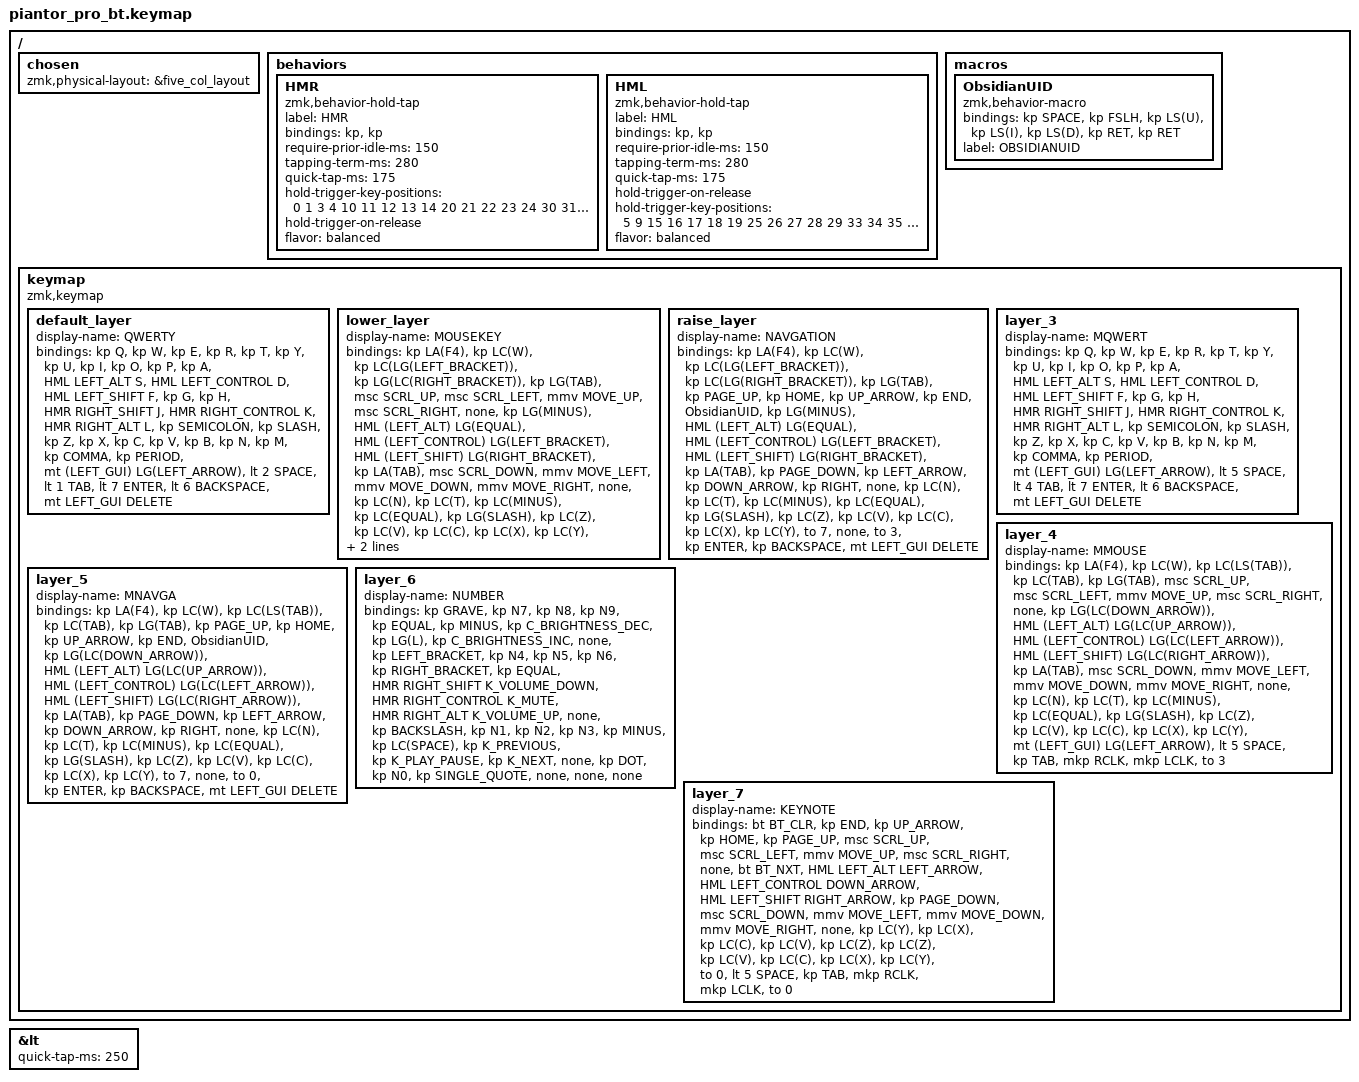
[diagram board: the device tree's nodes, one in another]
/*
 * Copyright (c) 2020 The ZMK Contributors
 *
 * SPDX-License-Identifier: MIT
 */

#include <behaviors.dtsi>
#include <dt-bindings/zmk/bt.h>
#include <dt-bindings/zmk/keys.h>
#include <dt-bindings/zmk/pointing.h>

&lt { quick-tap-ms = <250>; };

/ {
    chosen { zmk,physical-layout = &five_col_layout; };
};

/ {
    behaviors {
        HMR: HMR {
            compatible = "zmk,behavior-hold-tap";
            label = "HMR";
            bindings = <&kp>, <&kp>;

            #binding-cells = <2>;
            require-prior-idle-ms = <150>;
            tapping-term-ms = <280>;
            quick-tap-ms = <175>;
            hold-trigger-key-positions = <0 1 3 4 10 11 12 13 14 20 21 22 23 24 30 31 32 2>;
            hold-trigger-on-release;
            flavor = "balanced";
        };

        HML: HML {
            compatible = "zmk,behavior-hold-tap";
            label = "HML";
            bindings = <&kp>, <&kp>;

            #binding-cells = <2>;
            require-prior-idle-ms = <150>;
            tapping-term-ms = <280>;
            quick-tap-ms = <175>;
            hold-trigger-on-release;
            hold-trigger-key-positions = <5 9 15 16 17 18 19 25 26 27 28 29 33 34 35 6 7 8>;
            flavor = "balanced";
        };
    };

    macros {
        ObsidianUID: ObsidianUID {
            compatible = "zmk,behavior-macro";
            #binding-cells = <0>;
            bindings = <&kp SPACE &kp FSLH &kp LS(U) &kp LS(I) &kp LS(D) &kp RET &kp RET>;
            label = "OBSIDIANUID";
        };
    };

    keymap {
        compatible = "zmk,keymap";

        default_layer {
            display-name = "QWERTY";
            bindings = <
  &kp Q  &kp W  &kp E  &kp R  &kp T  &kp Y  &kp U  &kp I  &kp O  &kp P      &kp A  &HML LEFT_ALT S  &HML LEFT_CONTROL D  &HML LEFT_SHIFT F  &kp G  &kp H  &HMR RIGHT_SHIFT J  &HMR RIGHT_CONTROL K  &HMR RIGHT_ALT L  &kp SEMICOLON      &kp SLASH  &kp Z  &kp X  &kp C  &kp V  &kp B  &kp N  &kp M  &kp COMMA  &kp PERIOD    &mt (LEFT_GUI) LG(LEFT_ARROW)  &lt 2 SPACE  &lt 1 TAB  &lt 7 ENTER  &lt 6 BACKSPACE  &mt LEFT_GUI DELETE
            >;
        };

        lower_layer {
            display-name = "MOUSEKEY";
            bindings = <
  &kp LA(F4)  &kp LC(W)  &kp LC(LG(LEFT_BRACKET))  &kp LG(LC(RIGHT_BRACKET))  &kp LG(TAB)  &msc SCRL_UP  &msc SCRL_LEFT  &mmv MOVE_UP  &msc SCRL_RIGHT  &none      &kp LG(MINUS)  &HML (LEFT_ALT) LG(EQUAL)  &HML (LEFT_CONTROL) LG(LEFT_BRACKET)  &HML (LEFT_SHIFT) LG(RIGHT_BRACKET)  &kp LA(TAB)  &msc SCRL_DOWN  &mmv MOVE_LEFT  &mmv MOVE_DOWN  &mmv MOVE_RIGHT  &none      &kp LC(N)  &kp LC(T)  &kp LC(MINUS)  &kp LC(EQUAL)  &kp LG(SLASH)  &kp LC(Z)  &kp LC(V)  &kp LC(C)  &kp LC(X)  &kp LC(Y)    &mt (LEFT_GUI) LG(LEFT_ARROW)  &lt 2 SPACE  &kp TAB  &mkp RCLK  &mkp LCLK  &to 0
            >;
        };

        raise_layer {
            display-name = "NAVGATION";
            bindings = <
  &kp LA(F4)  &kp LC(W)  &kp LC(LG(LEFT_BRACKET))  &kp LC(LG(RIGHT_BRACKET))  &kp LG(TAB)  &kp PAGE_UP  &kp HOME  &kp UP_ARROW  &kp END  &ObsidianUID      &kp LG(MINUS)  &HML (LEFT_ALT) LG(EQUAL)  &HML (LEFT_CONTROL) LG(LEFT_BRACKET)  &HML (LEFT_SHIFT) LG(RIGHT_BRACKET)  &kp LA(TAB)  &kp PAGE_DOWN  &kp LEFT_ARROW  &kp DOWN_ARROW  &kp RIGHT  &none      &kp LC(N)  &kp LC(T)  &kp LC(MINUS)  &kp LC(EQUAL)  &kp LG(SLASH)  &kp LC(Z)  &kp LC(V)  &kp LC(C)  &kp LC(X)  &kp LC(Y)    &to 7  &none  &to 3  &kp ENTER  &kp BACKSPACE  &mt LEFT_GUI DELETE
            >;
        };

        layer_3 {
            display-name = "MQWERT";
            bindings = <
  &kp Q  &kp W  &kp E  &kp R  &kp T  &kp Y  &kp U  &kp I  &kp O  &kp P      &kp A  &HML LEFT_ALT S  &HML LEFT_CONTROL D  &HML LEFT_SHIFT F  &kp G  &kp H  &HMR RIGHT_SHIFT J  &HMR RIGHT_CONTROL K  &HMR RIGHT_ALT L  &kp SEMICOLON      &kp SLASH  &kp Z  &kp X  &kp C  &kp V  &kp B  &kp N  &kp M  &kp COMMA  &kp PERIOD    &mt (LEFT_GUI) LG(LEFT_ARROW)  &lt 5 SPACE  &lt 4 TAB  &lt 7 ENTER  &lt 6 BACKSPACE  &mt LEFT_GUI DELETE
            >;
        };

        layer_4 {
            display-name = "MMOUSE";
            bindings = <
  &kp LA(F4)  &kp LC(W)  &kp LC(LS(TAB))  &kp LC(TAB)  &kp LG(TAB)  &msc SCRL_UP  &msc SCRL_LEFT  &mmv MOVE_UP  &msc SCRL_RIGHT  &none      &kp LG(LC(DOWN_ARROW))  &HML (LEFT_ALT) LG(LC(UP_ARROW))  &HML (LEFT_CONTROL) LG(LC(LEFT_ARROW))  &HML (LEFT_SHIFT) LG(LC(RIGHT_ARROW))  &kp LA(TAB)  &msc SCRL_DOWN  &mmv MOVE_LEFT  &mmv MOVE_DOWN  &mmv MOVE_RIGHT  &none      &kp LC(N)  &kp LC(T)  &kp LC(MINUS)  &kp LC(EQUAL)  &kp LG(SLASH)  &kp LC(Z)  &kp LC(V)  &kp LC(C)  &kp LC(X)  &kp LC(Y)    &mt (LEFT_GUI) LG(LEFT_ARROW)  &lt 5 SPACE  &kp TAB  &mkp RCLK  &mkp LCLK  &to 3
            >;
        };

        layer_5 {
            display-name = "MNAVGA";
            bindings = <
  &kp LA(F4)  &kp LC(W)  &kp LC(LS(TAB))  &kp LC(TAB)  &kp LG(TAB)  &kp PAGE_UP  &kp HOME  &kp UP_ARROW  &kp END  &ObsidianUID      &kp LG(LC(DOWN_ARROW))  &HML (LEFT_ALT) LG(LC(UP_ARROW))  &HML (LEFT_CONTROL) LG(LC(LEFT_ARROW))  &HML (LEFT_SHIFT) LG(LC(RIGHT_ARROW))  &kp LA(TAB)  &kp PAGE_DOWN  &kp LEFT_ARROW  &kp DOWN_ARROW  &kp RIGHT  &none      &kp LC(N)  &kp LC(T)  &kp LC(MINUS)  &kp LC(EQUAL)  &kp LG(SLASH)  &kp LC(Z)  &kp LC(V)  &kp LC(C)  &kp LC(X)  &kp LC(Y)    &to 7  &none  &to 0  &kp ENTER  &kp BACKSPACE  &mt LEFT_GUI DELETE
            >;
        };

        layer_6 {
            display-name = "NUMBER";
            bindings = <
  &kp GRAVE  &kp N7  &kp N8  &kp N9  &kp EQUAL  &kp MINUS  &kp C_BRIGHTNESS_DEC  &kp LG(L)  &kp C_BRIGHTNESS_INC  &none      &kp LEFT_BRACKET  &kp N4  &kp N5  &kp N6  &kp RIGHT_BRACKET  &kp EQUAL  &HMR RIGHT_SHIFT K_VOLUME_DOWN  &HMR RIGHT_CONTROL K_MUTE  &HMR RIGHT_ALT K_VOLUME_UP  &none      &kp BACKSLASH  &kp N1  &kp N2  &kp N3  &kp MINUS  &kp LC(SPACE)  &kp K_PREVIOUS  &kp K_PLAY_PAUSE  &kp K_NEXT  &none    &kp DOT  &kp N0  &kp SINGLE_QUOTE  &none  &none  &none
            >;
        };

        layer_7 {
            display-name = "KEYNOTE";
            bindings = <
  &bt BT_CLR  &kp END  &kp UP_ARROW  &kp HOME  &kp PAGE_UP  &msc SCRL_UP  &msc SCRL_LEFT  &mmv MOVE_UP  &msc SCRL_RIGHT  &none      &bt BT_NXT  &HML LEFT_ALT LEFT_ARROW  &HML LEFT_CONTROL DOWN_ARROW  &HML LEFT_SHIFT RIGHT_ARROW  &kp PAGE_DOWN  &msc SCRL_DOWN  &mmv MOVE_LEFT  &mmv MOVE_DOWN  &mmv MOVE_RIGHT  &none      &kp LC(Y)  &kp LC(X)  &kp LC(C)  &kp LC(V)  &kp LC(Z)  &kp LC(Z)  &kp LC(V)  &kp LC(C)  &kp LC(X)  &kp LC(Y)    &to 0  &lt 5 SPACE  &kp TAB  &mkp RCLK  &mkp LCLK  &to 0
            >;
        };
    };
};
